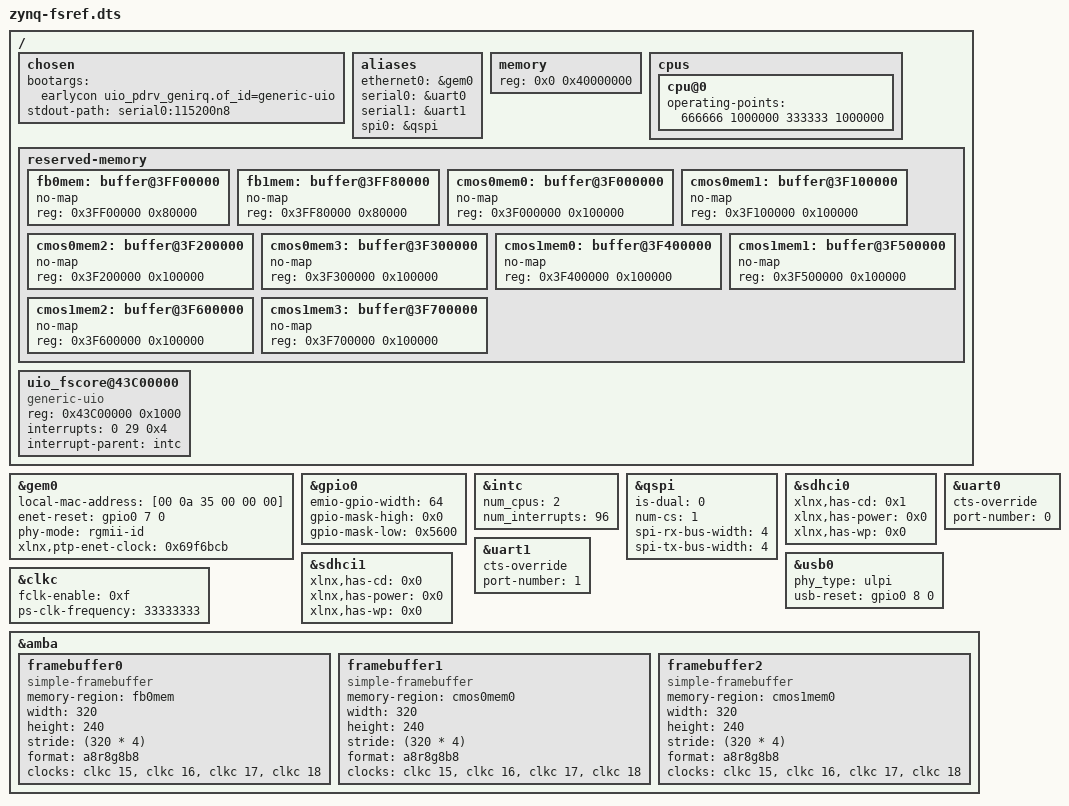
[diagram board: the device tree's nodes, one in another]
/*
 * system-top.dts
 * system.dts
 * pcw.dtsi
 * NOTE: we dropped pl.dtsi for fscore registers, but use uio instead.
 */

/dts-v1/;
/include/ "zynq-7000.dtsi"
/ {
	// copy from system-top.dts, add uio settings for bootargs
	chosen {
		bootargs = "earlycon uio_pdrv_genirq.of_id=generic-uio";
		stdout-path = "serial0:115200n8";
	};
	aliases {
		ethernet0 = &gem0;
		serial0 = &uart0;
		serial1 = &uart1;
		spi0 = &qspi;
	};
	memory {
		device_type = "memory";
		reg = <0x0 0x40000000>;
	};

	// copy from pcw.dtsi for clock settings
	cpus {
		cpu@0 {
			operating-points = <666666 1000000 333333 1000000>;
		};
	};

	// custom reserved memory for fixed buffers used by display and cmos sensor
	reserved-memory {
		#address-cells = <1>;
		#size-cells = <1>;
		ranges;

		fb0mem: buffer@3FF00000 {
			no-map;
			reg = <0x3FF00000 0x80000>;
		};

		fb1mem: buffer@3FF80000 {
			no-map;
			reg = <0x3FF80000 0x80000>;
		};

		cmos0mem0: buffer@3F000000 {
			no-map;
			reg = <0x3F000000 0x100000>;
		};

		cmos0mem1: buffer@3F100000 {
			no-map;
			reg = <0x3F100000 0x100000>;
		};

		cmos0mem2: buffer@3F200000 {
			no-map;
			reg = <0x3F200000 0x100000>;
		};

		cmos0mem3: buffer@3F300000 {
			no-map;
			reg = <0x3F300000 0x100000>;
		};

		cmos1mem0: buffer@3F400000 {
			no-map;
			reg = <0x3F400000 0x100000>;
		};

		cmos1mem1: buffer@3F500000 {
			no-map;
			reg = <0x3F500000 0x100000>;
		};

		cmos1mem2: buffer@3F600000 {
			no-map;
			reg = <0x3F600000 0x100000>;
		};

		cmos1mem3: buffer@3F700000 {
			no-map;
			reg = <0x3F700000 0x100000>;
		};
	};

	uio_fscore@43C00000 {
		compatible = "generic-uio";
		reg = < 0x43C00000 0x1000 >;
		interrupts = < 0 29 0x4 >;
		interrupt-parent = <&intc>;
	};
};

// copy from pcw.dtsi
// integrated the local-mac-address from system.dts
&gem0 {
	local-mac-address = [00 0a 35 00 00 00];
	enet-reset = <&gpio0 7 0>;
	phy-mode = "rgmii-id";
	status = "okay";
	xlnx,ptp-enet-clock = <0x69f6bcb>;
};
&gpio0 {
	emio-gpio-width = <64>;
	gpio-mask-high = <0x0>;
	gpio-mask-low = <0x5600>;
};
&intc {
	num_cpus = <2>;
	num_interrupts = <96>;
};
&qspi {
	is-dual = <0>;
	num-cs = <1>;
	spi-rx-bus-width = <4>;
	spi-tx-bus-width = <4>;
	status = "okay";
};
&sdhci0 {
	status = "okay";
	xlnx,has-cd = <0x1>;
	xlnx,has-power = <0x0>;
	xlnx,has-wp = <0x0>;
};
&sdhci1 {
	status = "okay";
	xlnx,has-cd = <0x0>;
	xlnx,has-power = <0x0>;
	xlnx,has-wp = <0x0>;
};
&uart0 {
	cts-override ;
	device_type = "serial";
	port-number = <0>;
	status = "okay";
};
&uart1 {
	cts-override ;
	device_type = "serial";
	port-number = <1>;
	status = "okay";
};
&usb0 {
	phy_type = "ulpi";
	status = "okay";
	usb-reset = <&gpio0 8 0>;
};
&clkc {
	fclk-enable = <0xf>;
	ps-clk-frequency = <33333333>;
};

// custom framebuffers
&amba {
	framebuffer0 {
		compatible = "simple-framebuffer";
		//reg = <0x3FF00000 (320 * 240 * 4)>;
		memory-region = <&fb0mem>;
		width = <320>;
		height = <240>;
		stride = <(320 * 4)>;
		format = "a8r8g8b8";
		clocks = <&clkc 15>, <&clkc 16>, <&clkc 17>, <&clkc 18>;
		// lcd-supply = <&reg_dc1sw>;
	};
	framebuffer1 {
		compatible = "simple-framebuffer";
		memory-region = <&cmos0mem0>;
		width = <320>;
		height = <240>;
		stride = <(320 * 4)>;
		format = "a8r8g8b8";
		clocks = <&clkc 15>, <&clkc 16>, <&clkc 17>, <&clkc 18>;
		// lcd-supply = <&reg_dc1sw>;
	};
	framebuffer2 {
		compatible = "simple-framebuffer";
		memory-region = <&cmos1mem0>;
		width = <320>;
		height = <240>;
		stride = <(320 * 4)>;
		format = "a8r8g8b8";
		clocks = <&clkc 15>, <&clkc 16>, <&clkc 17>, <&clkc 18>;
		// lcd-supply = <&reg_dc1sw>;
	};
};

